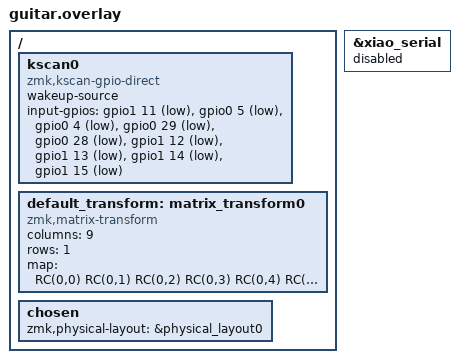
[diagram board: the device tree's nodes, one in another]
#include <dt-bindings/zmk/matrix_transform.h>
#include "guitar-layouts.dtsi"

/ {
    kscan0: kscan0 {
        compatible = "zmk,kscan-gpio-direct";
        wakeup-source;

        input-gpios = <
             &gpio1 11  (GPIO_ACTIVE_LOW | GPIO_PULL_UP)  
            &gpio0 5  (GPIO_ACTIVE_LOW | GPIO_PULL_UP) 
            &gpio0 4  (GPIO_ACTIVE_LOW | GPIO_PULL_UP) 
            &gpio0 29  (GPIO_ACTIVE_LOW | GPIO_PULL_UP) 
            &gpio0 28  (GPIO_ACTIVE_LOW | GPIO_PULL_UP)          
            &gpio1 12 (GPIO_ACTIVE_LOW | GPIO_PULL_UP)  
            &gpio1 13 (GPIO_ACTIVE_LOW | GPIO_PULL_UP) 
            &gpio1 14 (GPIO_ACTIVE_LOW | GPIO_PULL_UP)  
            &gpio1 15 (GPIO_ACTIVE_LOW | GPIO_PULL_UP)  
        >;
    };
};
&xiao_serial { 
    status = "disabled"; 
};

/ {

    default_transform: matrix_transform0 {
            compatible = "zmk,matrix-transform";
            columns = <9>;
            rows = <1>;
            map = <
            RC(0,0) 
            RC(0,1)
            RC(0,2) 
            RC(0,3) 
            RC(0,4) 
            RC(0,5) 
            RC(0,6) 
            RC(0,7) 
            RC(0,8) 
        >;
    };
};


/ {
    chosen {
        zmk,physical-layout = &physical_layout0;
    };
};
